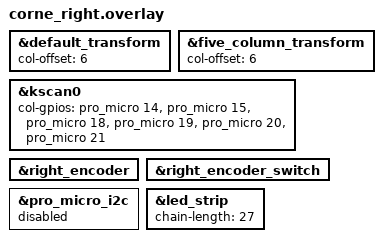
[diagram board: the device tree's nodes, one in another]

#include "corne.dtsi"

&default_transform {
    col-offset = <6>;
};

&five_column_transform {
    col-offset = <6>;
};

&kscan0 {
    col-gpios
        = <&pro_micro 14 GPIO_ACTIVE_HIGH>
        , <&pro_micro 15 GPIO_ACTIVE_HIGH>
        , <&pro_micro 18 GPIO_ACTIVE_HIGH>
        , <&pro_micro 19 GPIO_ACTIVE_HIGH>
        , <&pro_micro 20 GPIO_ACTIVE_HIGH>
        , <&pro_micro 21 GPIO_ACTIVE_HIGH>
        ;
};

&right_encoder {
	status = "okay";
};

&right_encoder_switch {
    status = "okay";
};

&pro_micro_i2c {
    status = "disabled";  // Disable I2C on right for encoder
};

&led_strip {
    chain-length = <27>;
};
